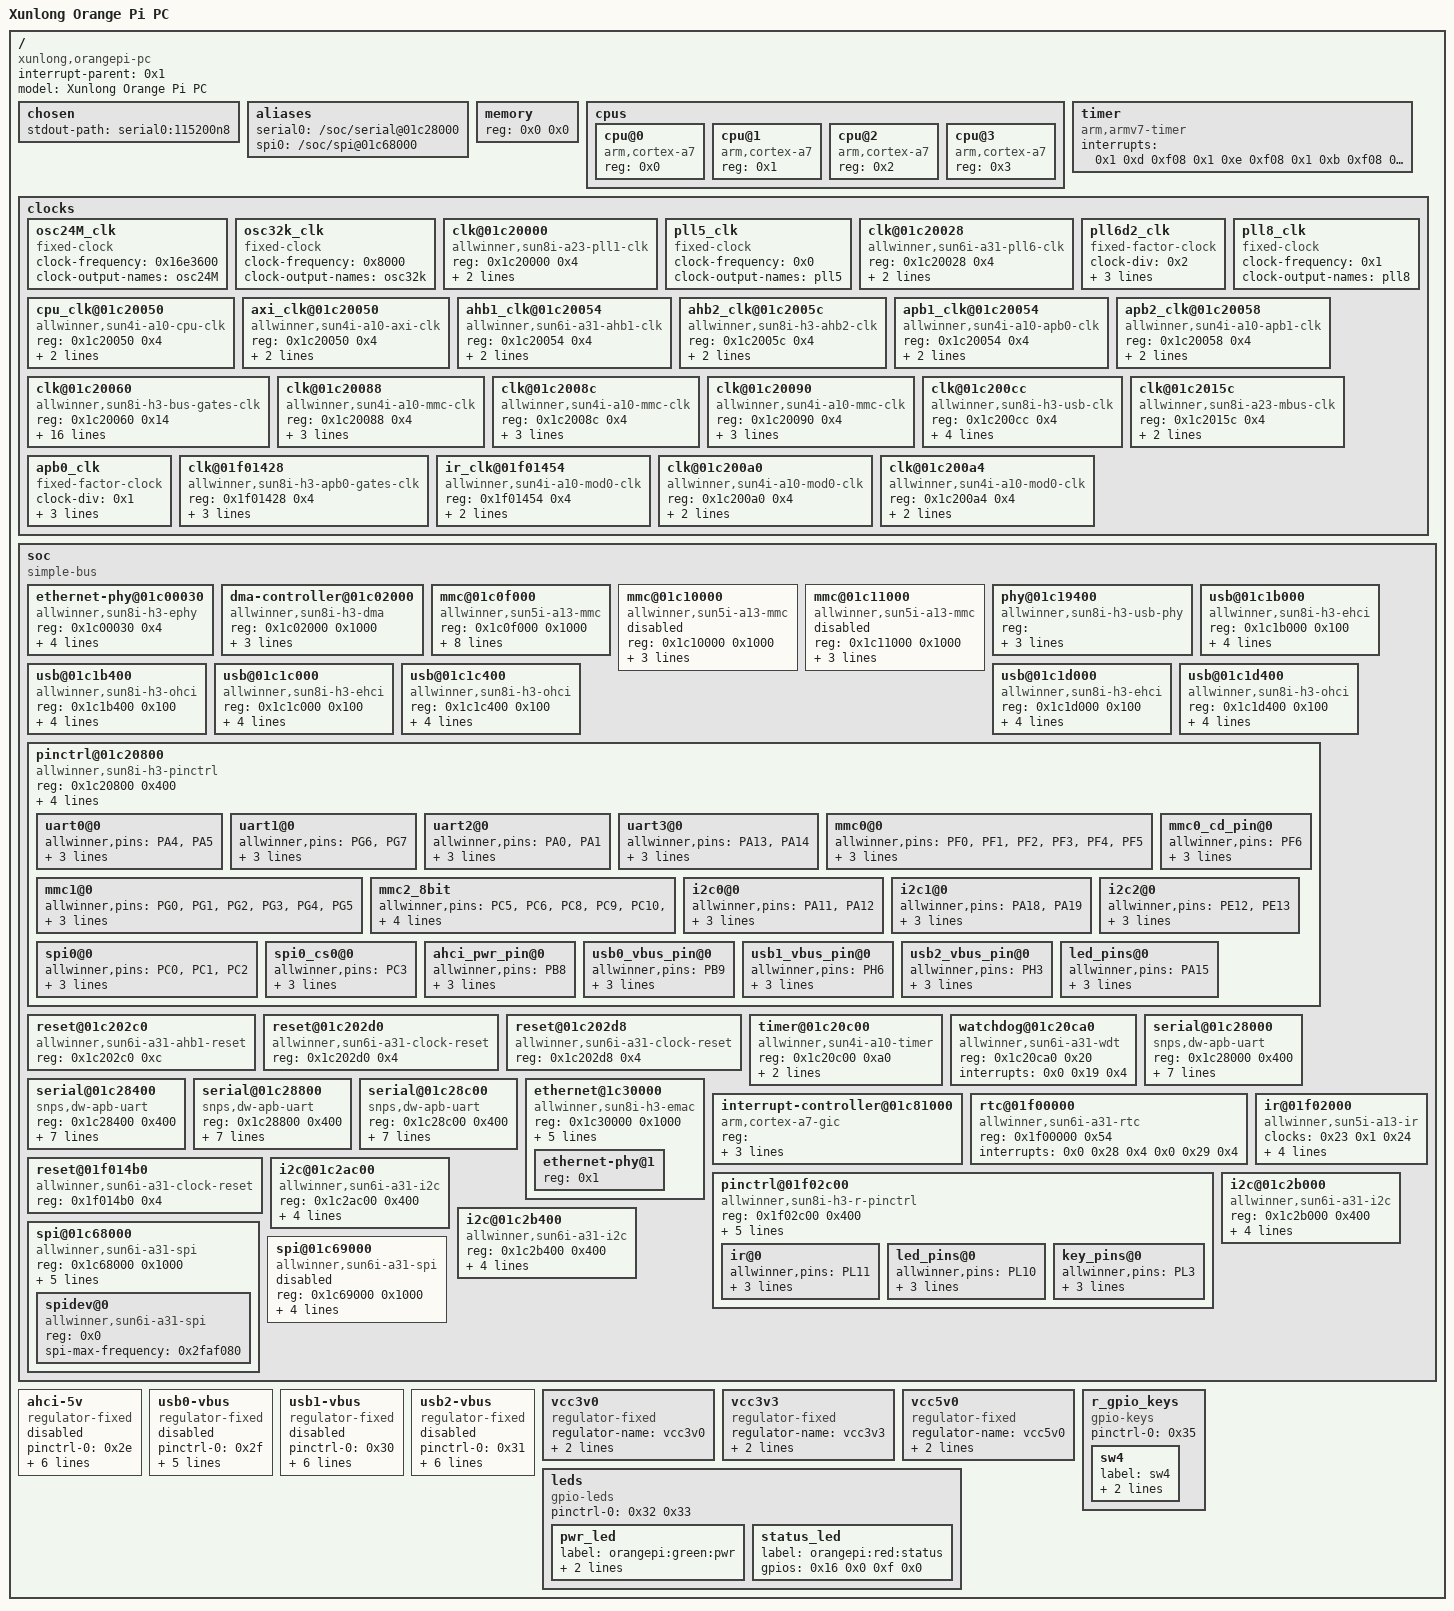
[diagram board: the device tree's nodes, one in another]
/dts-v1/;

/ {
	#address-cells = <0x1>;
	#size-cells = <0x1>;
	interrupt-parent = <0x1>;
	model = "Xunlong Orange Pi PC";
	compatible = "xunlong,orangepi-pc", "allwinner,sun8i-h3";

	chosen {
		stdout-path = "serial0:115200n8";
	};

	aliases {
		serial0 = "/soc/serial@01c28000";
		spi0 = "/soc/spi@01c68000";
	};

	memory {
		device_type = "memory";
		reg = <0x0 0x0>;
	};

	cpus {
		#address-cells = <0x1>;
		#size-cells = <0x0>;

		cpu@0 {
			compatible = "arm,cortex-a7";
			device_type = "cpu";
			reg = <0x0>;
		};

		cpu@1 {
			compatible = "arm,cortex-a7";
			device_type = "cpu";
			reg = <0x1>;
		};

		cpu@2 {
			compatible = "arm,cortex-a7";
			device_type = "cpu";
			reg = <0x2>;
		};

		cpu@3 {
			compatible = "arm,cortex-a7";
			device_type = "cpu";
			reg = <0x3>;
		};
	};

	timer {
		compatible = "arm,armv7-timer";
		interrupts = <0x1 0xd 0xf08 0x1 0xe 0xf08 0x1 0xb 0xf08 0x1 0xa 0xf08>;
	};

	clocks {
		#address-cells = <0x1>;
		#size-cells = <0x1>;
		ranges;

		osc24M_clk {
			#clock-cells = <0x0>;
			compatible = "fixed-clock";
			clock-frequency = <0x16e3600>;
			clock-output-names = "osc24M";
			linux,phandle = <0x2>;
			phandle = <0x2>;
		};

		osc32k_clk {
			#clock-cells = <0x0>;
			compatible = "fixed-clock";
			clock-frequency = <0x8000>;
			clock-output-names = "osc32k";
			linux,phandle = <0x4>;
			phandle = <0x4>;
		};

		clk@01c20000 {
			#clock-cells = <0x0>;
			compatible = "allwinner,sun8i-a23-pll1-clk";
			reg = <0x1c20000 0x4>;
			clocks = <0x2>;
			clock-output-names = "pll1";
			linux,phandle = <0x5>;
			phandle = <0x5>;
		};

		pll5_clk {
			#clock-cells = <0x0>;
			compatible = "fixed-clock";
			clock-frequency = <0x0>;
			clock-output-names = "pll5";
			linux,phandle = <0xe>;
			phandle = <0xe>;
		};

		clk@01c20028 {
			#clock-cells = <0x1>;
			compatible = "allwinner,sun6i-a31-pll6-clk";
			reg = <0x1c20028 0x4>;
			clocks = <0x2>;
			clock-output-names = "pll6", "pll6x2";
			linux,phandle = <0x3>;
			phandle = <0x3>;
		};

		pll6d2_clk {
			#clock-cells = <0x0>;
			compatible = "fixed-factor-clock";
			clock-div = <0x2>;
			clock-mult = <0x1>;
			clocks = <0x3 0x0>;
			clock-output-names = "pll6d2";
			linux,phandle = <0x9>;
			phandle = <0x9>;
		};

		pll8_clk {
			#clock-cells = <0x0>;
			compatible = "fixed-clock";
			clock-frequency = <0x1>;
			clock-output-names = "pll8";
			linux,phandle = <0xd>;
			phandle = <0xd>;
		};

		cpu_clk@01c20050 {
			#clock-cells = <0x0>;
			compatible = "allwinner,sun4i-a10-cpu-clk";
			reg = <0x1c20050 0x4>;
			clocks = <0x4 0x2 0x5 0x5>;
			clock-output-names = "cpu";
			linux,phandle = <0x6>;
			phandle = <0x6>;
		};

		axi_clk@01c20050 {
			#clock-cells = <0x0>;
			compatible = "allwinner,sun4i-a10-axi-clk";
			reg = <0x1c20050 0x4>;
			clocks = <0x6>;
			clock-output-names = "axi";
			linux,phandle = <0x7>;
			phandle = <0x7>;
		};

		ahb1_clk@01c20054 {
			#clock-cells = <0x0>;
			compatible = "allwinner,sun6i-a31-ahb1-clk";
			reg = <0x1c20054 0x4>;
			clocks = <0x4 0x2 0x7 0x3 0x0>;
			clock-output-names = "ahb1";
			linux,phandle = <0x8>;
			phandle = <0x8>;
		};

		ahb2_clk@01c2005c {
			#clock-cells = <0x0>;
			compatible = "allwinner,sun8i-h3-ahb2-clk";
			reg = <0x1c2005c 0x4>;
			clocks = <0x8 0x9>;
			clock-output-names = "ahb2";
			linux,phandle = <0xa>;
			phandle = <0xa>;
		};

		apb1_clk@01c20054 {
			#clock-cells = <0x0>;
			compatible = "allwinner,sun4i-a10-apb0-clk";
			reg = <0x1c20054 0x4>;
			clocks = <0x8>;
			clock-output-names = "apb1";
			linux,phandle = <0xb>;
			phandle = <0xb>;
		};

		apb2_clk@01c20058 {
			#clock-cells = <0x0>;
			compatible = "allwinner,sun4i-a10-apb1-clk";
			reg = <0x1c20058 0x4>;
			clocks = <0x4 0x2 0x3 0x0 0x3 0x0>;
			clock-output-names = "apb2";
			linux,phandle = <0xc>;
			phandle = <0xc>;
		};

		clk@01c20060 {
			#clock-cells = <0x1>;
			compatible = "allwinner,sun8i-h3-bus-gates-clk";
			reg = <0x1c20060 0x14>;
			clocks = <0x8 0xa 0xb 0xc>;
			clock-names = "ahb1", "ahb2", "apb1", "apb2";
			clock-indices = <0x5 0x6 0x8 0x9 0xa 0xd 0xe 0x11 0x12 0x13 0x14 0x15 0x17 0x18 0x19 0x1a 0x1b 0x1c 0x1d 0x1e 0x1f 0x20 0x23 0x24 0x25 0x28 0x29 0x2b 0x2c 0x34 0x35 0x36 0x40 0x41 0x45 0x48 0x4c 0x4d 0x4e 0x60 0x61 0x62 0x70 0x71 0x72 0x73 0x74 0x80 0x87>;
			clock-output-names = "bus_ce", "bus_dma", "bus_mmc0", "bus_mmc1", "bus_mmc2", "bus_nand", "bus_sdram", "bus_gmac", "bus_ts", "bus_hstimer", "bus_spi0", "bus_spi1", "bus_otg", "bus_otg_ehci0", "bus_ehci1", "bus_ehci2", "bus_ehci3", "bus_otg_ohci0", "bus_ohci1", "bus_ohci2", "bus_ohci3", "bus_ve", "bus_lcd0", "bus_lcd1", "bus_deint", "bus_csi", "bus_tve", "bus_hdmi", "bus_de", "bus_gpu", "bus_msgbox", "bus_spinlock", "bus_codec", "bus_spdif", "bus_pio", "bus_ths", "bus_i2s0", "bus_i2s1", "bus_i2s2", "bus_i2c0", "bus_i2c1", "bus_i2c2", "bus_uart0", "bus_uart1", "bus_uart2", "bus_uart3", "bus_scr", "bus_ephy", "bus_dbg";
			linux,phandle = <0x10>;
			phandle = <0x10>;
		};

		clk@01c20088 {
			#clock-cells = <0x1>;
			compatible = "allwinner,sun4i-a10-mmc-clk";
			reg = <0x1c20088 0x4>;
			clocks = <0x2 0x3 0x0 0xd>;
			clock-output-names = "mmc0", "mmc0_output", "mmc0_sample";
			linux,phandle = <0x12>;
			phandle = <0x12>;
		};

		clk@01c2008c {
			#clock-cells = <0x1>;
			compatible = "allwinner,sun4i-a10-mmc-clk";
			reg = <0x1c2008c 0x4>;
			clocks = <0x2 0x3 0x0 0xd>;
			clock-output-names = "mmc1", "mmc1_output", "mmc1_sample";
			linux,phandle = <0x17>;
			phandle = <0x17>;
		};

		clk@01c20090 {
			#clock-cells = <0x1>;
			compatible = "allwinner,sun4i-a10-mmc-clk";
			reg = <0x1c20090 0x4>;
			clocks = <0x2 0x3 0x0 0xd>;
			clock-output-names = "mmc2", "mmc2_output", "mmc2_sample";
			linux,phandle = <0x18>;
			phandle = <0x18>;
		};

		clk@01c200cc {
			#clock-cells = <0x1>;
			#reset-cells = <0x1>;
			compatible = "allwinner,sun8i-h3-usb-clk";
			reg = <0x1c200cc 0x4>;
			clocks = <0x2>;
			clock-output-names = "usb_phy0", "usb_phy1", "usb_phy2", "usb_phy3", "usb_ohci0", "usb_ohci1", "usb_ohci2", "usb_ohci3";
			linux,phandle = <0x19>;
			phandle = <0x19>;
		};

		clk@01c2015c {
			#clock-cells = <0x0>;
			compatible = "allwinner,sun8i-a23-mbus-clk";
			reg = <0x1c2015c 0x4>;
			clocks = <0x2 0x3 0x1 0xe>;
			clock-output-names = "mbus";
		};

		apb0_clk {
			compatible = "fixed-factor-clock";
			#clock-cells = <0x0>;
			clock-div = <0x1>;
			clock-mult = <0x1>;
			clocks = <0x2>;
			clock-output-names = "apb0";
			linux,phandle = <0xf>;
			phandle = <0xf>;
		};

		clk@01f01428 {
			compatible = "allwinner,sun8i-h3-apb0-gates-clk", "allwinner,sun4i-a10-gates-clk";
			reg = <0x1f01428 0x4>;
			#clock-cells = <0x1>;
			clocks = <0xf>;
			clock-indices = <0x0 0x1>;
			clock-output-names = "apb0_pio", "apb0_ir";
			linux,phandle = <0x23>;
			phandle = <0x23>;
		};

		ir_clk@01f01454 {
			compatible = "allwinner,sun4i-a10-mod0-clk";
			reg = <0x1f01454 0x4>;
			#clock-cells = <0x0>;
			clocks = <0x4 0x2>;
			clock-output-names = "ir";
			linux,phandle = <0x24>;
			phandle = <0x24>;
		};

		clk@01c200a0 {
			#clock-cells = <0x0>;
			compatible = "allwinner,sun4i-a10-mod0-clk";
			reg = <0x1c200a0 0x4>;
			clocks = <0x2 0x3 0x0>;
			clock-output-names = "spi0";
			linux,phandle = <0x2a>;
			phandle = <0x2a>;
		};

		clk@01c200a4 {
			#clock-cells = <0x0>;
			compatible = "allwinner,sun4i-a10-mod0-clk";
			reg = <0x1c200a4 0x4>;
			clocks = <0x2 0x3 0x0>;
			clock-output-names = "spi1";
			linux,phandle = <0x2d>;
			phandle = <0x2d>;
		};
	};

	soc {
		compatible = "simple-bus";
		#address-cells = <0x1>;
		#size-cells = <0x1>;
		ranges;

		ethernet-phy@01c00030 {
			compatible = "allwinner,sun8i-h3-ephy";
			reg = <0x1c00030 0x4>;
			clocks = <0x10 0x80>;
			resets = <0x11 0x42>;
			#clock-cells = <0x0>;
			clock-output-names = "emac_tx";
			allwinner,ephy-addr = <0x1>;
			linux,phandle = <0x21>;
			phandle = <0x21>;
		};

		dma-controller@01c02000 {
			compatible = "allwinner,sun8i-h3-dma";
			reg = <0x1c02000 0x1000>;
			interrupts = <0x0 0x32 0x4>;
			clocks = <0x10 0x6>;
			resets = <0x11 0x6>;
			#dma-cells = <0x1>;
			linux,phandle = <0x1c>;
			phandle = <0x1c>;
		};

		mmc@01c0f000 {
			compatible = "allwinner,sun5i-a13-mmc";
			reg = <0x1c0f000 0x1000>;
			clocks = <0x10 0x8 0x12 0x0 0x12 0x1 0x12 0x2>;
			clock-names = "ahb", "mmc", "output", "sample";
			resets = <0x11 0x8>;
			reset-names = "ahb";
			interrupts = <0x0 0x3c 0x4>;
			status = "okay";
			#address-cells = <0x1>;
			#size-cells = <0x0>;
			pinctrl-names = "default";
			pinctrl-0 = <0x13 0x14>;
			vmmc-supply = <0x15>;
			bus-width = <0x4>;
			cd-gpios = <0x16 0x5 0x6 0x0>;
			cd-inverted;
		};

		mmc@01c10000 {
			compatible = "allwinner,sun5i-a13-mmc";
			reg = <0x1c10000 0x1000>;
			clocks = <0x10 0x9 0x17 0x0 0x17 0x1 0x17 0x2>;
			clock-names = "ahb", "mmc", "output", "sample";
			resets = <0x11 0x9>;
			reset-names = "ahb";
			interrupts = <0x0 0x3d 0x4>;
			status = "disabled";
			#address-cells = <0x1>;
			#size-cells = <0x0>;
		};

		mmc@01c11000 {
			compatible = "allwinner,sun5i-a13-mmc";
			reg = <0x1c11000 0x1000>;
			clocks = <0x10 0xa 0x18 0x0 0x18 0x1 0x18 0x2>;
			clock-names = "ahb", "mmc", "output", "sample";
			resets = <0x11 0xa>;
			reset-names = "ahb";
			interrupts = <0x0 0x3e 0x4>;
			status = "disabled";
			#address-cells = <0x1>;
			#size-cells = <0x0>;
		};

		phy@01c19400 {
			compatible = "allwinner,sun8i-h3-usb-phy";
			reg = <0x1c19400 0x2c 0x1c1a800 0x4 0x1c1b800 0x4 0x1c1c800 0x4 0x1c1d800 0x4>;
			reg-names = "phy_ctrl", "pmu0", "pmu1", "pmu2", "pmu3";
			clocks = <0x19 0x8 0x19 0x9 0x19 0xa 0x19 0xb>;
			clock-names = "usb0_phy", "usb1_phy", "usb2_phy", "usb3_phy";
			resets = <0x19 0x0 0x19 0x1 0x19 0x2 0x19 0x3>;
			reset-names = "usb0_reset", "usb1_reset", "usb2_reset", "usb3_reset";
			status = "okay";
			#phy-cells = <0x1>;
			linux,phandle = <0x1a>;
			phandle = <0x1a>;
		};

		usb@01c1b000 {
			compatible = "allwinner,sun8i-h3-ehci", "generic-ehci";
			reg = <0x1c1b000 0x100>;
			interrupts = <0x0 0x4a 0x4>;
			clocks = <0x10 0x19 0x10 0x1d>;
			resets = <0x11 0x19 0x11 0x1d>;
			phys = <0x1a 0x1>;
			phy-names = "usb";
			status = "okay";
		};

		usb@01c1b400 {
			compatible = "allwinner,sun8i-h3-ohci", "generic-ohci";
			reg = <0x1c1b400 0x100>;
			interrupts = <0x0 0x4b 0x4>;
			clocks = <0x10 0x1d 0x10 0x19 0x19 0x11>;
			resets = <0x11 0x1d 0x11 0x19>;
			phys = <0x1a 0x1>;
			phy-names = "usb";
			status = "okay";
		};

		usb@01c1c000 {
			compatible = "allwinner,sun8i-h3-ehci", "generic-ehci";
			reg = <0x1c1c000 0x100>;
			interrupts = <0x0 0x4c 0x4>;
			clocks = <0x10 0x1a 0x10 0x1e>;
			resets = <0x11 0x1a 0x11 0x1e>;
			phys = <0x1a 0x2>;
			phy-names = "usb";
			status = "okay";
		};

		usb@01c1c400 {
			compatible = "allwinner,sun8i-h3-ohci", "generic-ohci";
			reg = <0x1c1c400 0x100>;
			interrupts = <0x0 0x4d 0x4>;
			clocks = <0x10 0x1e 0x10 0x1a 0x19 0x12>;
			resets = <0x11 0x1e 0x11 0x1a>;
			phys = <0x1a 0x2>;
			phy-names = "usb";
			status = "okay";
		};

		usb@01c1d000 {
			compatible = "allwinner,sun8i-h3-ehci", "generic-ehci";
			reg = <0x1c1d000 0x100>;
			interrupts = <0x0 0x4e 0x4>;
			clocks = <0x10 0x1b 0x10 0x1f>;
			resets = <0x11 0x1b 0x11 0x1f>;
			phys = <0x1a 0x3>;
			phy-names = "usb";
			status = "okay";
		};

		usb@01c1d400 {
			compatible = "allwinner,sun8i-h3-ohci", "generic-ohci";
			reg = <0x1c1d400 0x100>;
			interrupts = <0x0 0x4f 0x4>;
			clocks = <0x10 0x1f 0x10 0x1b 0x19 0x13>;
			resets = <0x11 0x1f 0x11 0x1b>;
			phys = <0x1a 0x3>;
			phy-names = "usb";
			status = "okay";
		};

		pinctrl@01c20800 {
			compatible = "allwinner,sun8i-h3-pinctrl";
			reg = <0x1c20800 0x400>;
			interrupts = <0x0 0xb 0x4 0x0 0x11 0x4>;
			clocks = <0x10 0x45>;
			gpio-controller;
			#gpio-cells = <0x3>;
			interrupt-controller;
			#interrupt-cells = <0x3>;
			linux,phandle = <0x16>;
			phandle = <0x16>;

			uart0@0 {
				allwinner,pins = "PA4", "PA5";
				allwinner,function = "uart0";
				allwinner,drive = <0x0>;
				allwinner,pull = <0x0>;
				linux,phandle = <0x1d>;
				phandle = <0x1d>;
			};

			uart1@0 {
				allwinner,pins = "PG6", "PG7";
				allwinner,function = "uart1";
				allwinner,drive = <0x0>;
				allwinner,pull = <0x0>;
				linux,phandle = <0x1e>;
				phandle = <0x1e>;
			};

			uart2@0 {
				allwinner,pins = "PA0", "PA1";
				allwinner,function = "uart2";
				allwinner,drive = <0x0>;
				allwinner,pull = <0x0>;
				linux,phandle = <0x1f>;
				phandle = <0x1f>;
			};

			uart3@0 {
				allwinner,pins = "PA13", "PA14";
				allwinner,function = "uart3";
				allwinner,drive = <0x0>;
				allwinner,pull = <0x0>;
				linux,phandle = <0x20>;
				phandle = <0x20>;
			};

			mmc0@0 {
				allwinner,pins = "PF0", "PF1", "PF2", "PF3", "PF4", "PF5";
				allwinner,function = "mmc0";
				allwinner,drive = <0x2>;
				allwinner,pull = <0x0>;
				linux,phandle = <0x13>;
				phandle = <0x13>;
			};

			mmc0_cd_pin@0 {
				allwinner,pins = "PF6";
				allwinner,function = "gpio_in";
				allwinner,drive = <0x0>;
				allwinner,pull = <0x1>;
				linux,phandle = <0x14>;
				phandle = <0x14>;
			};

			mmc1@0 {
				allwinner,pins = "PG0", "PG1", "PG2", "PG3", "PG4", "PG5";
				allwinner,function = "mmc1";
				allwinner,drive = <0x2>;
				allwinner,pull = <0x0>;
			};

			mmc2_8bit {
				allwinner,pins = "PC5", "PC6", "PC8", "PC9", "PC10", "PC11", "PC12", "PC13", "PC14", "PC15", "PC16";
				allwinner,function = "mmc2";
				allwinner,drive = <0x2>;
				allwinner,pull = <0x0>;
			};

			i2c0@0 {
				allwinner,pins = "PA11", "PA12";
				allwinner,function = "i2c0";
				allwinner,drive = <0x0>;
				allwinner,pull = <0x0>;
				linux,phandle = <0x27>;
				phandle = <0x27>;
			};

			i2c1@0 {
				allwinner,pins = "PA18", "PA19";
				allwinner,function = "i2c1";
				allwinner,drive = <0x0>;
				allwinner,pull = <0x0>;
				linux,phandle = <0x28>;
				phandle = <0x28>;
			};

			i2c2@0 {
				allwinner,pins = "PE12", "PE13";
				allwinner,function = "i2c2";
				allwinner,drive = <0x0>;
				allwinner,pull = <0x0>;
				linux,phandle = <0x29>;
				phandle = <0x29>;
			};

			spi0@0 {
				allwinner,pins = "PC0", "PC1", "PC2";
				allwinner,function = "spi0";
				allwinner,drive = <0x0>;
				allwinner,pull = <0x0>;
				linux,phandle = <0x2b>;
				phandle = <0x2b>;
			};

			spi0_cs0@0 {
				allwinner,pins = "PC3";
				allwinner,function = "spi0";
				allwinner,drive = <0x0>;
				allwinner,pull = <0x0>;
				linux,phandle = <0x2c>;
				phandle = <0x2c>;
			};

			ahci_pwr_pin@0 {
				allwinner,pins = "PB8";
				allwinner,function = "gpio_out";
				allwinner,drive = <0x0>;
				allwinner,pull = <0x0>;
				linux,phandle = <0x2e>;
				phandle = <0x2e>;
			};

			usb0_vbus_pin@0 {
				allwinner,pins = "PB9";
				allwinner,function = "gpio_out";
				allwinner,drive = <0x0>;
				allwinner,pull = <0x0>;
				linux,phandle = <0x2f>;
				phandle = <0x2f>;
			};

			usb1_vbus_pin@0 {
				allwinner,pins = "PH6";
				allwinner,function = "gpio_out";
				allwinner,drive = <0x0>;
				allwinner,pull = <0x0>;
				linux,phandle = <0x30>;
				phandle = <0x30>;
			};

			usb2_vbus_pin@0 {
				allwinner,pins = "PH3";
				allwinner,function = "gpio_out";
				allwinner,drive = <0x0>;
				allwinner,pull = <0x0>;
				linux,phandle = <0x31>;
				phandle = <0x31>;
			};

			led_pins@0 {
				allwinner,pins = "PA15";
				allwinner,function = "gpio_out";
				allwinner,drive = <0x0>;
				allwinner,pull = <0x0>;
				linux,phandle = <0x32>;
				phandle = <0x32>;
			};
		};

		reset@01c202c0 {
			#reset-cells = <0x1>;
			compatible = "allwinner,sun6i-a31-ahb1-reset";
			reg = <0x1c202c0 0xc>;
			linux,phandle = <0x11>;
			phandle = <0x11>;
		};

		reset@01c202d0 {
			#reset-cells = <0x1>;
			compatible = "allwinner,sun6i-a31-clock-reset";
			reg = <0x1c202d0 0x4>;
		};

		reset@01c202d8 {
			#reset-cells = <0x1>;
			compatible = "allwinner,sun6i-a31-clock-reset";
			reg = <0x1c202d8 0x4>;
			linux,phandle = <0x1b>;
			phandle = <0x1b>;
		};

		timer@01c20c00 {
			compatible = "allwinner,sun4i-a10-timer";
			reg = <0x1c20c00 0xa0>;
			interrupts = <0x0 0x12 0x4 0x0 0x13 0x4>;
			clocks = <0x2>;
		};

		watchdog@01c20ca0 {
			compatible = "allwinner,sun6i-a31-wdt";
			reg = <0x1c20ca0 0x20>;
			interrupts = <0x0 0x19 0x4>;
		};

		serial@01c28000 {
			compatible = "snps,dw-apb-uart";
			reg = <0x1c28000 0x400>;
			interrupts = <0x0 0x0 0x4>;
			reg-shift = <0x2>;
			reg-io-width = <0x4>;
			clocks = <0x10 0x70>;
			resets = <0x1b 0x10>;
			dmas = <0x1c 0x6 0x1c 0x6>;
			dma-names = "rx", "tx";
			status = "okay";
			pinctrl-names = "default";
			pinctrl-0 = <0x1d>;
		};

		serial@01c28400 {
			compatible = "snps,dw-apb-uart";
			reg = <0x1c28400 0x400>;
			interrupts = <0x0 0x1 0x4>;
			reg-shift = <0x2>;
			reg-io-width = <0x4>;
			clocks = <0x10 0x71>;
			resets = <0x1b 0x11>;
			dmas = <0x1c 0x7 0x1c 0x7>;
			dma-names = "rx", "tx";
			status = "okay";
			pinctrl-names = "default";
			pinctrl-0 = <0x1e>;
		};

		serial@01c28800 {
			compatible = "snps,dw-apb-uart";
			reg = <0x1c28800 0x400>;
			interrupts = <0x0 0x2 0x4>;
			reg-shift = <0x2>;
			reg-io-width = <0x4>;
			clocks = <0x10 0x72>;
			resets = <0x1b 0x12>;
			dmas = <0x1c 0x8 0x1c 0x8>;
			dma-names = "rx", "tx";
			status = "okay";
			pinctrl-names = "default";
			pinctrl-0 = <0x1f>;
		};

		serial@01c28c00 {
			compatible = "snps,dw-apb-uart";
			reg = <0x1c28c00 0x400>;
			interrupts = <0x0 0x3 0x4>;
			reg-shift = <0x2>;
			reg-io-width = <0x4>;
			clocks = <0x10 0x73>;
			resets = <0x1b 0x13>;
			dmas = <0x1c 0x9 0x1c 0x9>;
			dma-names = "rx", "tx";
			status = "okay";
			pinctrl-names = "default";
			pinctrl-0 = <0x20>;
		};

		ethernet@1c30000 {
			compatible = "allwinner,sun8i-h3-emac";
			reg = <0x1c30000 0x1000>;
			interrupts = <0x0 0x52 0x4>;
			resets = <0x11 0x11>;
			reset-names = "ahb";
			clocks = <0x10 0x11 0x21>;
			clock-names = "ahb", "tx";
			#address-cells = <0x1>;
			#size-cells = <0x0>;
			phy = <0x22>;
			phy-mode = "mii";
			status = "okay";

			ethernet-phy@1 {
				reg = <0x1>;
				linux,phandle = <0x22>;
				phandle = <0x22>;
			};
		};

		interrupt-controller@01c81000 {
			compatible = "arm,cortex-a7-gic", "arm,cortex-a15-gic";
			reg = <0x1c81000 0x1000 0x1c82000 0x1000 0x1c84000 0x2000 0x1c86000 0x2000>;
			interrupt-controller;
			#interrupt-cells = <0x3>;
			interrupts = <0x1 0x9 0xf04>;
			linux,phandle = <0x1>;
			phandle = <0x1>;
		};

		rtc@01f00000 {
			compatible = "allwinner,sun6i-a31-rtc";
			reg = <0x1f00000 0x54>;
			interrupts = <0x0 0x28 0x4 0x0 0x29 0x4>;
		};

		reset@01f014b0 {
			reg = <0x1f014b0 0x4>;
			compatible = "allwinner,sun6i-a31-clock-reset";
			#reset-cells = <0x1>;
			linux,phandle = <0x25>;
			phandle = <0x25>;
		};

		ir@01f02000 {
			compatible = "allwinner,sun5i-a13-ir";
			clocks = <0x23 0x1 0x24>;
			clock-names = "apb", "ir";
			resets = <0x25 0x1>;
			interrupts = <0x0 0x25 0x4>;
			reg = <0x1f02000 0x40>;
			status = "okay";
			pinctrl-names = "default";
			pinctrl-0 = <0x26>;
		};

		pinctrl@01f02c00 {
			compatible = "allwinner,sun8i-h3-r-pinctrl";
			reg = <0x1f02c00 0x400>;
			interrupts = <0x0 0x2d 0x4>;
			clocks = <0x23 0x0>;
			resets = <0x25 0x0>;
			gpio-controller;
			#gpio-cells = <0x3>;
			interrupt-controller;
			#interrupt-cells = <0x3>;
			linux,phandle = <0x34>;
			phandle = <0x34>;

			ir@0 {
				allwinner,pins = "PL11";
				allwinner,function = "s_cir_rx";
				allwinner,drive = <0x0>;
				allwinner,pull = <0x0>;
				linux,phandle = <0x26>;
				phandle = <0x26>;
			};

			led_pins@0 {
				allwinner,pins = "PL10";
				allwinner,function = "gpio_out";
				allwinner,drive = <0x0>;
				allwinner,pull = <0x0>;
				linux,phandle = <0x33>;
				phandle = <0x33>;
			};

			key_pins@0 {
				allwinner,pins = "PL3";
				allwinner,function = "gpio_in";
				allwinner,drive = <0x0>;
				allwinner,pull = <0x0>;
				linux,phandle = <0x35>;
				phandle = <0x35>;
			};
		};

		i2c@01c2ac00 {
			compatible = "allwinner,sun6i-a31-i2c";
			reg = <0x1c2ac00 0x400>;
			interrupts = <0x0 0x6 0x4>;
			clocks = <0x10 0x60>;
			resets = <0x1b 0x0>;
			status = "okay";
			#address-cells = <0x1>;
			#size-cells = <0x0>;
			pinctrl-names = "default";
			pinctrl-0 = <0x27>;
		};

		i2c@01c2b000 {
			compatible = "allwinner,sun6i-a31-i2c";
			reg = <0x1c2b000 0x400>;
			interrupts = <0x0 0x7 0x4>;
			clocks = <0x10 0x61>;
			resets = <0x1b 0x1>;
			status = "okay";
			#address-cells = <0x1>;
			#size-cells = <0x0>;
			pinctrl-names = "default";
			pinctrl-0 = <0x28>;
		};

		i2c@01c2b400 {
			compatible = "allwinner,sun6i-a31-i2c";
			reg = <0x1c2b400 0x400>;
			interrupts = <0x0 0x8 0x4>;
			clocks = <0x10 0x62>;
			resets = <0x1b 0x2>;
			status = "okay";
			#address-cells = <0x1>;
			#size-cells = <0x0>;
			pinctrl-names = "default";
			pinctrl-0 = <0x29>;
		};

		spi@01c68000 {
			compatible = "allwinner,sun6i-a31-spi";
			reg = <0x1c68000 0x1000>;
			interrupts = <0x0 0x41 0x4>;
			clocks = <0x10 0x14 0x2a>;
			clock-names = "ahb", "mod";
			dmas = <0x1c 0x17 0x1c 0x17>;
			dma-names = "rx", "tx";
			resets = <0x11 0x14>;
			status = "okay";
			#address-cells = <0x1>;
			#size-cells = <0x0>;
			pinctrl-names = "default";
			pinctrl-0 = <0x2b 0x2c>;

			spidev@0 {
				compatible = "allwinner,sun6i-a31-spi";
				reg = <0x0>;
				spi-max-frequency = <0x2faf080>;
			};
		};

		spi@01c69000 {
			compatible = "allwinner,sun6i-a31-spi";
			reg = <0x1c69000 0x1000>;
			interrupts = <0x0 0x42 0x4>;
			clocks = <0x10 0x15 0x2d>;
			clock-names = "ahb", "mod";
			dmas = <0x1c 0x18 0x1c 0x18>;
			dma-names = "rx", "tx";
			resets = <0x11 0x15>;
			status = "disabled";
		};
	};

	ahci-5v {
		compatible = "regulator-fixed";
		pinctrl-names = "default";
		pinctrl-0 = <0x2e>;
		regulator-name = "ahci-5v";
		regulator-min-microvolt = <0x4c4b40>;
		regulator-max-microvolt = <0x4c4b40>;
		regulator-boot-on;
		enable-active-high;
		gpio = <0x16 0x1 0x8 0x0>;
		status = "disabled";
	};

	usb0-vbus {
		compatible = "regulator-fixed";
		pinctrl-names = "default";
		pinctrl-0 = <0x2f>;
		regulator-name = "usb0-vbus";
		regulator-min-microvolt = <0x4c4b40>;
		regulator-max-microvolt = <0x4c4b40>;
		enable-active-high;
		gpio = <0x16 0x1 0x9 0x0>;
		status = "disabled";
	};

	usb1-vbus {
		compatible = "regulator-fixed";
		pinctrl-names = "default";
		pinctrl-0 = <0x30>;
		regulator-name = "usb1-vbus";
		regulator-min-microvolt = <0x4c4b40>;
		regulator-max-microvolt = <0x4c4b40>;
		regulator-boot-on;
		enable-active-high;
		gpio = <0x16 0x7 0x6 0x0>;
		status = "disabled";
	};

	usb2-vbus {
		compatible = "regulator-fixed";
		pinctrl-names = "default";
		pinctrl-0 = <0x31>;
		regulator-name = "usb2-vbus";
		regulator-min-microvolt = <0x4c4b40>;
		regulator-max-microvolt = <0x4c4b40>;
		regulator-boot-on;
		enable-active-high;
		gpio = <0x16 0x7 0x3 0x0>;
		status = "disabled";
	};

	vcc3v0 {
		compatible = "regulator-fixed";
		regulator-name = "vcc3v0";
		regulator-min-microvolt = <0x2dc6c0>;
		regulator-max-microvolt = <0x2dc6c0>;
	};

	vcc3v3 {
		compatible = "regulator-fixed";
		regulator-name = "vcc3v3";
		regulator-min-microvolt = <0x325aa0>;
		regulator-max-microvolt = <0x325aa0>;
		linux,phandle = <0x15>;
		phandle = <0x15>;
	};

	vcc5v0 {
		compatible = "regulator-fixed";
		regulator-name = "vcc5v0";
		regulator-min-microvolt = <0x4c4b40>;
		regulator-max-microvolt = <0x4c4b40>;
	};

	leds {
		compatible = "gpio-leds";
		pinctrl-names = "default";
		pinctrl-0 = <0x32 0x33>;

		pwr_led {
			label = "orangepi:green:pwr";
			gpios = <0x34 0x0 0xa 0x0>;
			default-state = "on";
		};

		status_led {
			label = "orangepi:red:status";
			gpios = <0x16 0x0 0xf 0x0>;
		};
	};

	r_gpio_keys {
		compatible = "gpio-keys";
		pinctrl-names = "default";
		pinctrl-0 = <0x35>;

		sw4 {
			label = "sw4";
			linux,code = <0x100>;
			gpios = <0x34 0x0 0x3 0x1>;
		};
	};
};
